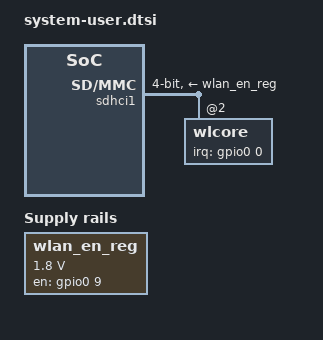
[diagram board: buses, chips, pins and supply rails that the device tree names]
/include/ "system-conf.dtsi"
/ {
	chosen {
		bootargs = "console=ttyPS0,115200 earlycon root=/dev/mmcblk0p2 rw rootwait earlyprintk uio_pdrv_genirq.of_id=generic-uio";
	};

    wlan_en_reg: fixed-regulator-wlen {
		compatible = "regulator-fixed";
		regulator-name = "wlan-en-regulator";
		regulator-min-microvolt = <1800000>;
		regulator-max-microvolt = <1800000>;
		gpio = <&gpio0 9 4>;
		startup-delay-us = <70000>;
		enable-active-high;
	};
};

&sdhci1 {
	status = "okay";
	vmmc-supply = <&wlan_en_reg>;
	bus-width = <4>;
	cap-power-off-card;
	keep-power-in-suspend;
	#address-cells = <1>;
	#size-cells = <0>;

	wlcore: wlcore@0 {
		reg = <2>;
		interrupt-parent = <&gpio0>;
		interrupts = <0 4>;
	};
};

&axi_bram_ctrl_0{
    compatible = "generic-uio";
};

&led_driver_test_0{
    compatible = "generic-uio";
};

&wlcore {
	compatible = "wlcore", "ti,wl1837";
};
